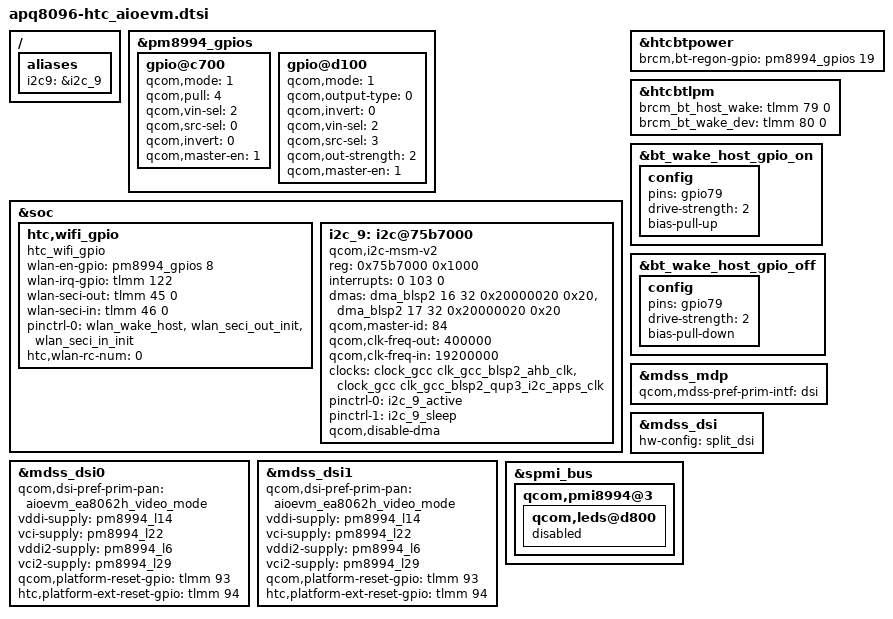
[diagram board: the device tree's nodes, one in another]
/* Copyright (c) 2016, The Linux Foundation. All rights reserved.
 *
 * This program is free software; you can redistribute it and/or modify
 * it under the terms of the GNU General Public License version 2 and
 * only version 2 as published by the Free Software Foundation.
 *
 * This program is distributed in the hope that it will be useful,
 * but WITHOUT ANY WARRANTY; without even the implied warranty of
 * MERCHANTABILITY or FITNESS FOR A PARTICULAR PURPOSE.  See the
 * GNU General Public License for more details.
 */


#include "apq8096-audio-aio.dtsi" //HTC_AUD
#include "msm8996-htc-common.dtsi"
#include "apq8096-htc_aio-nanohub-v2.dtsi"
#include "apq8096-battery-aio.dtsi"
#include "apq8096-htc_aio-pinctrl.dtsi"
#include "apq8096-htc_aio-regulator.dtsi"
#include "apq8096-htc_aio-usb.dtsi"
#include "dsi-panel-aioevm-samsung-ea8062h.dtsi" /* HTC_DISP */
#include "apq8096-htc_aio-key.dtsi"

&pm8994_gpios {
	gpio@c700 { /* GPIO 8 - BCM 4359 WLAN_EN */
		qcom,mode = <1>;		/* Digital output*/
		qcom,pull = <4>;		/* Pulldown 10uA */
		qcom,vin-sel = <2>;		/* VIN2 */
		qcom,src-sel = <0>;		/* GPIO */
		qcom,invert = <0>;		/* Invert */
		qcom,master-en = <1>;		/* Enable GPIO */
		status = "okay";
	};

	gpio@d100 { /* GPIO 18 - BCM4359 WLAN 32K Clock */
		qcom,mode = <1>;		/* Digital output */
		qcom,output-type = <0>;		/* CMOS logic */
		qcom,invert = <0>;		/* Output low initially */
		qcom,vin-sel = <2>;		/* VIN 2 */
		qcom,src-sel = <3>;		/* Function 2 */
		qcom,out-strength = <2>;	/* Medium */
		qcom,master-en = <1>;		/* Enable GPIO */
		status = "okay";
	};
};

/* HTC_WIFI_START */
// ** HPKB[#6821] Platform patches
&soc {
	htc,wifi_gpio {
		compatible = "htc_wifi_gpio";
		wlan-en-gpio = <&pm8994_gpios 8 0>;
		wlan-irq-gpio = <&tlmm 122 0>;
		wlan-seci-out = <&tlmm 45 0>;
		wlan-seci-in = <&tlmm 46 0>;
		pinctrl-names = "default";
		pinctrl-0 = <&wlan_wake_host &wlan_seci_out_init &wlan_seci_in_init>;
		htc,wlan-rc-num = <0>;
	};
};
/* HTC_WIFI_END */

// [HTC_BT] +++
&htcbtpower {
        brcm,bt-regon-gpio = <&pm8994_gpios 19 0>; /* O2 BT_EN */
};

&htcbtlpm {
        brcm_bt_host_wake = <&tlmm 79 0>; /* BT_WAKE_HOST */
        brcm_bt_wake_dev  = <&tlmm 80 0>; /* BT_WAKE_DEV */
};

&bt_wake_host_gpio_on {
	config {
		pins = "gpio79";
		drive-strength = <2>;
		bias-pull-up;
	};
};

&bt_wake_host_gpio_off {
	config {
		pins = "gpio79";
		drive-strength = <2>;
		bias-pull-down;
	};
};
// [HTC_BT] ---

&soc {
	i2c_9: i2c@75b7000 { /* BLSP2 QUP3 */
		compatible = "qcom,i2c-msm-v2";
		#address-cells = <1>;
		#size-cells = <0>;
		reg-names = "qup_phys_addr";
		reg = <0x75b7000 0x1000>;
		interrupt-names = "qup_irq";
		interrupts = <0 103 0>;
		dmas = <&dma_blsp2 16 32 0x20000020 0x20>,
			<&dma_blsp2 17 32 0x20000020 0x20>;
		dma-names = "tx", "rx";
		qcom,master-id = <84>;
		qcom,clk-freq-out = <400000>;
		qcom,clk-freq-in  = <19200000>;
		clock-names = "iface_clk", "core_clk";
		clocks = <&clock_gcc clk_gcc_blsp2_ahb_clk>,
			 <&clock_gcc clk_gcc_blsp2_qup3_i2c_apps_clk>;
		pinctrl-names = "i2c_active", "i2c_sleep";
		pinctrl-0 = <&i2c_9_active>;
		pinctrl-1 = <&i2c_9_sleep>;
		qcom,disable-dma;
	};
};

/ {
    aliases {
        i2c9 = &i2c_9;
    };
};

/* HTC_DISP_START */
&mdss_mdp {
    qcom,mdss-pref-prim-intf = "dsi";
};

&mdss_dsi {
    hw-config = "split_dsi";
};

&mdss_dsi0 {
    qcom,dsi-pref-prim-pan = <&aioevm_ea8062h_video_mode>;
    pinctrl-names = "mdss_default", "mdss_sleep";

    vddi-supply = <&pm8994_l14>;
    vci-supply = <&pm8994_l22>;
    vddi2-supply = <&pm8994_l6>;
    vci2-supply = <&pm8994_l29>;

    /delete-property/ qcom,platform-te-gpio;
    /delete-property/ qcom,platform-bklight-en-gpio;
    qcom,platform-reset-gpio = <&tlmm 93 0>;
    htc,platform-ext-reset-gpio = <&tlmm 94 0>;
};

&mdss_dsi1 {
    qcom,dsi-pref-prim-pan = <&aioevm_ea8062h_video_mode>;
    pinctrl-names = "mdss_default", "mdss_sleep";

    vddi-supply = <&pm8994_l14>;
    vci-supply = <&pm8994_l22>;
    vddi2-supply = <&pm8994_l6>;
    vci2-supply = <&pm8994_l29>;

    /delete-property/ qcom,platform-te-gpio;
    /delete-property/ qcom,platform-bklight-en-gpio;
    qcom,platform-reset-gpio = <&tlmm 93 0>;
    htc,platform-ext-reset-gpio = <&tlmm 94 0>;
};

//Disable WLED for power saving
&spmi_bus {
    qcom,pmi8994@3 {
        qcom,leds@d800 {
            status = "disabled";
        };
    };
};
/* HTC_DISP_END */
